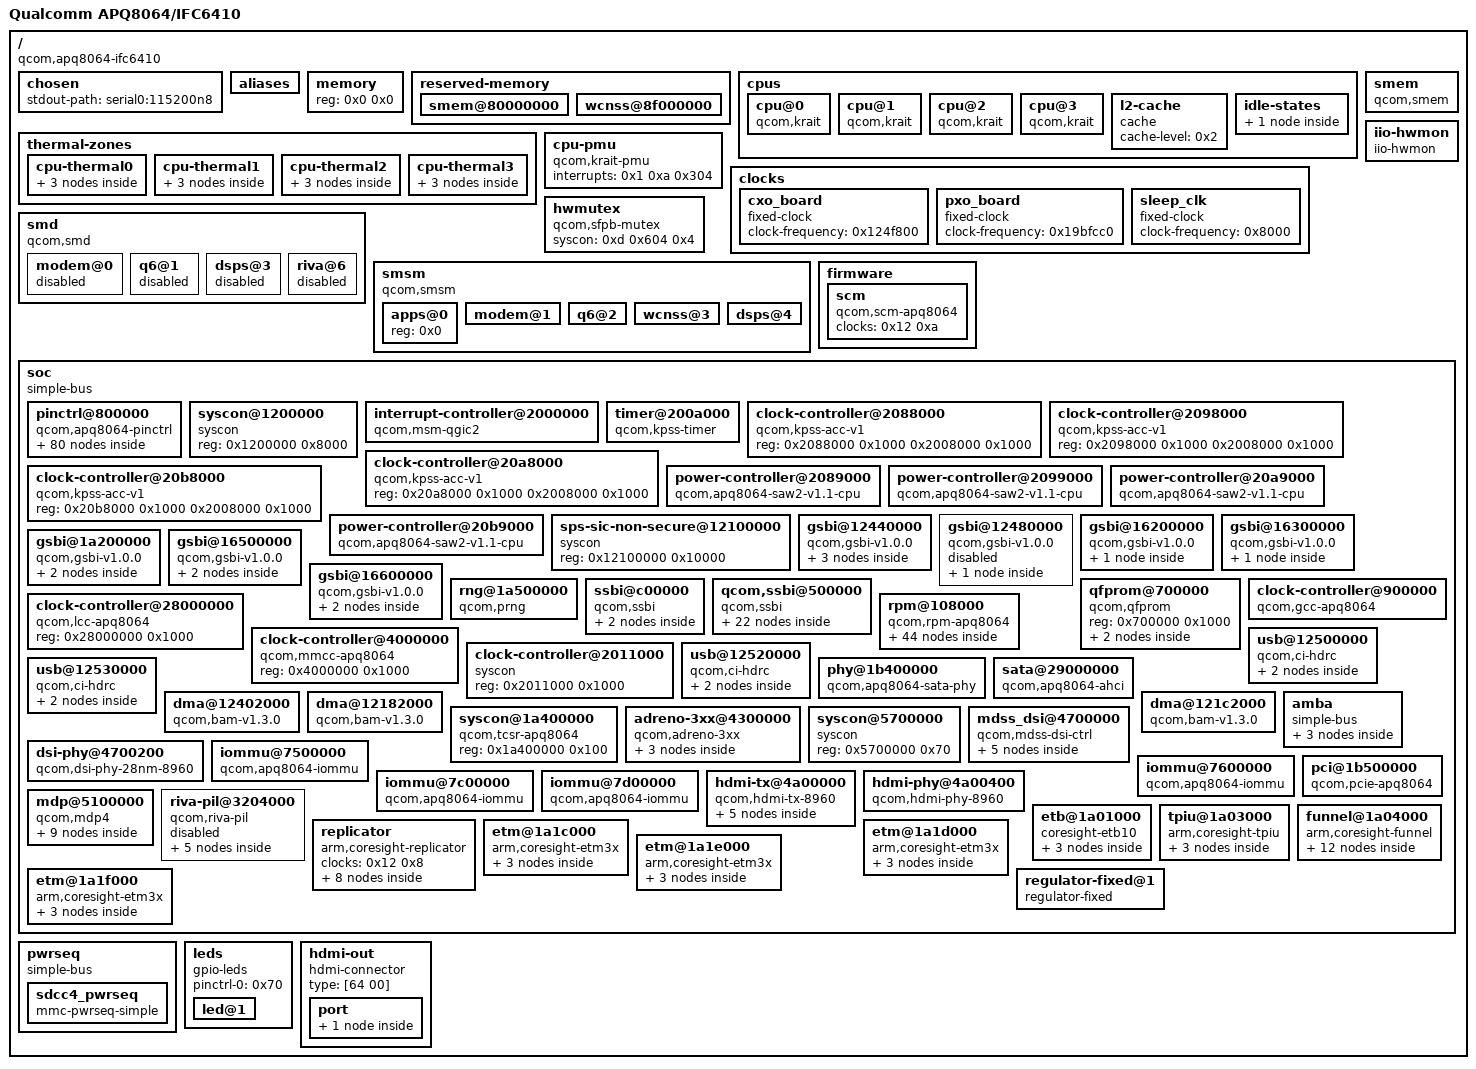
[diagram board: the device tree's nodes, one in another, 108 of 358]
/*
 * The code contained herein is licensed under the GNU General Public
 * License. You may obtain a copy of the GNU General Public License
 * Version 2 or later at the following locations:
 *
 * http://www.opensource.org/licenses/gpl-license.html
 * http://www.gnu.org/copyleft/gpl.html
 *
 * @TAG(OTHER_GPL)
 */

/dts-v1/;

/ {
	#address-cells = <0x1>;
	#size-cells = <0x1>;
	model = "Qualcomm APQ8064/IFC6410";
	compatible = "qcom,apq8064-ifc6410", "qcom,apq8064";
	interrupt-parent = <0x1>;

	chosen {
		stdout-path = "serial0:115200n8";
	};

	aliases {
		serial0 = "/soc/gsbi@16600000/serial@16640000";
		serial1 = "/soc/gsbi@16500000/serial@16540000";
		i2c0 = "/soc/gsbi@12440000/i2c@12460000";
		i2c1 = "/soc/gsbi@12480000/i2c@124a0000";
		i2c2 = "/soc/gsbi@16200000/i2c@16280000";
		i2c3 = "/soc/gsbi@16300000/i2c@16380000";
		spi0 = "/soc/gsbi@1a200000/spi@1a280000";
	};

	memory {
		device_type = "memory";
		reg = <0x0 0x0>;
	};

	reserved-memory {
		#address-cells = <0x1>;
		#size-cells = <0x1>;
		ranges;

		smem@80000000 {
			reg = <0x80000000 0x200000>;
			no-map;
			phandle = <0xe>;
		};

		wcnss@8f000000 {
			reg = <0x8f000000 0x700000>;
			no-map;
			phandle = <0x55>;
		};
	};

	cpus {
		#address-cells = <0x1>;
		#size-cells = <0x0>;

		cpu@0 {
			compatible = "qcom,krait";
			enable-method = "qcom,kpss-acc-v1";
			device_type = "cpu";
			reg = <0x0>;
			next-level-cache = <0x2>;
			qcom,acc = <0x3>;
			qcom,saw = <0x4>;
			cpu-idle-states = <0x5>;
			phandle = <0x66>;
		};

		cpu@1 {
			compatible = "qcom,krait";
			enable-method = "qcom,kpss-acc-v1";
			device_type = "cpu";
			reg = <0x1>;
			next-level-cache = <0x2>;
			qcom,acc = <0x6>;
			qcom,saw = <0x7>;
			cpu-idle-states = <0x5>;
			phandle = <0x68>;
		};

		cpu@2 {
			compatible = "qcom,krait";
			enable-method = "qcom,kpss-acc-v1";
			device_type = "cpu";
			reg = <0x2>;
			next-level-cache = <0x2>;
			qcom,acc = <0x8>;
			qcom,saw = <0x9>;
			cpu-idle-states = <0x5>;
			phandle = <0x6a>;
		};

		cpu@3 {
			compatible = "qcom,krait";
			enable-method = "qcom,kpss-acc-v1";
			device_type = "cpu";
			reg = <0x3>;
			next-level-cache = <0x2>;
			qcom,acc = <0xa>;
			qcom,saw = <0xb>;
			cpu-idle-states = <0x5>;
			phandle = <0x6c>;
		};

		l2-cache {
			compatible = "cache";
			cache-level = <0x2>;
			phandle = <0x2>;
		};

		idle-states {

			spc {
				compatible = "qcom,idle-state-spc", "arm,idle-state";
				entry-latency-us = <0x190>;
				exit-latency-us = <0x384>;
				min-residency-us = <0xbb8>;
				phandle = <0x5>;
			};
		};
	};

	thermal-zones {

		cpu-thermal0 {
			polling-delay-passive = <0xfa>;
			polling-delay = <0x3e8>;
			thermal-sensors = <0xc 0x7>;
			coefficients = <0x4af 0x0>;

			trips {

				trip0 {
					temperature = <0x124f8>;
					hysteresis = <0x7d0>;
					type = "passive";
				};

				trip1 {
					temperature = <0x1adb0>;
					hysteresis = <0x7d0>;
					type = "critical";
				};
			};
		};

		cpu-thermal1 {
			polling-delay-passive = <0xfa>;
			polling-delay = <0x3e8>;
			thermal-sensors = <0xc 0x8>;
			coefficients = <0x46c 0x0>;

			trips {

				trip0 {
					temperature = <0x124f8>;
					hysteresis = <0x7d0>;
					type = "passive";
				};

				trip1 {
					temperature = <0x1adb0>;
					hysteresis = <0x7d0>;
					type = "critical";
				};
			};
		};

		cpu-thermal2 {
			polling-delay-passive = <0xfa>;
			polling-delay = <0x3e8>;
			thermal-sensors = <0xc 0x9>;
			coefficients = <0x4af 0x0>;

			trips {

				trip0 {
					temperature = <0x124f8>;
					hysteresis = <0x7d0>;
					type = "passive";
				};

				trip1 {
					temperature = <0x1adb0>;
					hysteresis = <0x7d0>;
					type = "critical";
				};
			};
		};

		cpu-thermal3 {
			polling-delay-passive = <0xfa>;
			polling-delay = <0x3e8>;
			thermal-sensors = <0xc 0xa>;
			coefficients = <0x46c 0x0>;

			trips {

				trip0 {
					temperature = <0x124f8>;
					hysteresis = <0x7d0>;
					type = "passive";
				};

				trip1 {
					temperature = <0x1adb0>;
					hysteresis = <0x7d0>;
					type = "critical";
				};
			};
		};
	};

	cpu-pmu {
		compatible = "qcom,krait-pmu";
		interrupts = <0x1 0xa 0x304>;
	};

	clocks {

		cxo_board {
			compatible = "fixed-clock";
			#clock-cells = <0x0>;
			clock-frequency = <0x124f800>;
			phandle = <0x2f>;
		};

		pxo_board {
			compatible = "fixed-clock";
			#clock-cells = <0x0>;
			clock-frequency = <0x19bfcc0>;
		};

		sleep_clk {
			compatible = "fixed-clock";
			#clock-cells = <0x0>;
			clock-frequency = <0x8000>;
			phandle = <0x2e>;
		};
	};

	hwmutex {
		compatible = "qcom,sfpb-mutex";
		syscon = <0xd 0x604 0x4>;
		#hwlock-cells = <0x1>;
		phandle = <0xf>;
	};

	smem {
		compatible = "qcom,smem";
		memory-region = <0xe>;
		hwlocks = <0xf 0x3>;
	};

	smd {
		compatible = "qcom,smd";

		modem@0 {
			interrupts = <0x0 0x25 0x1>;
			qcom,ipc = <0x10 0x8 0x3>;
			qcom,smd-edge = <0x0>;
			status = "disabled";
		};

		q6@1 {
			interrupts = <0x0 0x5a 0x1>;
			qcom,ipc = <0x10 0x8 0xf>;
			qcom,smd-edge = <0x1>;
			status = "disabled";
		};

		dsps@3 {
			interrupts = <0x0 0x8a 0x1>;
			qcom,ipc = <0x11 0x4080 0x0>;
			qcom,smd-edge = <0x3>;
			status = "disabled";
		};

		riva@6 {
			interrupts = <0x0 0xc6 0x1>;
			qcom,ipc = <0x10 0x8 0x19>;
			qcom,smd-edge = <0x6>;
			status = "disabled";
		};
	};

	smsm {
		compatible = "qcom,smsm";
		#address-cells = <0x1>;
		#size-cells = <0x0>;
		qcom,ipc-1 = <0x10 0x8 0x4>;
		qcom,ipc-2 = <0x10 0x8 0xe>;
		qcom,ipc-3 = <0x10 0x8 0x17>;
		qcom,ipc-4 = <0x11 0x4094 0x0>;

		apps@0 {
			reg = <0x0>;
			#qcom,smem-state-cells = <0x1>;
			phandle = <0x5b>;
		};

		modem@1 {
			reg = <0x1>;
			interrupts = <0x0 0x26 0x1>;
			interrupt-controller;
			#interrupt-cells = <0x2>;
		};

		q6@2 {
			reg = <0x2>;
			interrupts = <0x0 0x59 0x1>;
			interrupt-controller;
			#interrupt-cells = <0x2>;
		};

		wcnss@3 {
			reg = <0x3>;
			interrupts = <0x0 0xcc 0x1>;
			interrupt-controller;
			#interrupt-cells = <0x2>;
			phandle = <0x54>;
		};

		dsps@4 {
			reg = <0x4>;
			interrupts = <0x0 0x89 0x1>;
			interrupt-controller;
			#interrupt-cells = <0x2>;
		};
	};

	firmware {

		scm {
			compatible = "qcom,scm-apq8064";
			clocks = <0x12 0xa>;
			clock-names = "core";
		};
	};

	iio-hwmon {
		compatible = "iio-hwmon";
		io-channels = <0x13 0x0 0x1 0x13 0x0 0x2 0x13 0x0 0x4 0x13 0x0 0xb 0x13 0x0 0xc 0x13 0x0 0xd 0x13 0x0 0xe>;
	};

	soc {
		#address-cells = <0x1>;
		#size-cells = <0x1>;
		ranges;
		compatible = "simple-bus";

		pinctrl@800000 {
			compatible = "qcom,apq8064-pinctrl";
			reg = <0x800000 0x4000>;
			gpio-controller;
			#gpio-cells = <0x2>;
			interrupt-controller;
			#interrupt-cells = <0x2>;
			interrupts = <0x0 0x10 0x4>;
			pinctrl-names = "default";
			pinctrl-0 = <0x14>;
			phandle = <0x20>;

			sdc4-gpios {
				phandle = <0x40>;

				pios {
					pins = "gpio63", "gpio64", "gpio65", "gpio66", "gpio67", "gpio68";
					function = "sdc4";
				};
			};

			sdcc1-pin-active {
				phandle = <0x39>;

				clk {
					pins = "sdc1_clk";
					drive-strengh = <0x10>;
					bias-disable;
				};

				cmd {
					pins = "sdc1_cmd";
					drive-strengh = <0xa>;
					bias-pull-up;
				};

				data {
					pins = "sdc1_data";
					drive-strengh = <0xa>;
					bias-pull-up;
				};
			};

			sdcc3-pin-active {

				clk {
					pins = "sdc3_clk";
					drive-strengh = <0x8>;
					bias-disable;
				};

				cmd {
					pins = "sdc3_cmd";
					drive-strengh = <0x8>;
					bias-pull-up;
				};

				data {
					pins = "sdc3_data";
					drive-strengh = <0x8>;
					bias-pull-up;
				};
			};

			ps_hold {
				phandle = <0x14>;

				mux {
					pins = "gpio78";
					function = "ps_hold";
				};
			};

			i2c1 {
				phandle = <0x16>;

				mux {
					pins = "gpio20", "gpio21";
					function = "gsbi1";
				};

				pinconf {
					pins = "gpio20", "gpio21";
					drive-strength = <0x10>;
					bias-disable;
				};
			};

			i2c1_pins_sleep {
				phandle = <0x17>;

				mux {
					pins = "gpio20", "gpio21";
					function = "gpio";
				};

				pinconf {
					pins = "gpio20", "gpio21";
					drive-strength = <0x2>;
					bias-disable = <0x0>;
				};
			};

			gsbi1_uart_2pins {

				mux {
					pins = "gpio18", "gpio19";
					function = "gsbi1";
				};
			};

			gsbi1_uart_4pins {

				mux {
					pins = "gpio18", "gpio19", "gpio20", "gpio21";
					function = "gsbi1";
				};
			};

			i2c2 {
				phandle = <0x18>;

				mux {
					pins = "gpio24", "gpio25";
					function = "gsbi2";
				};

				pinconf {
					pins = "gpio24", "gpio25";
					drive-strength = <0x10>;
					bias-disable;
				};
			};

			i2c2_pins_sleep {
				phandle = <0x19>;

				mux {
					pins = "gpio24", "gpio25";
					function = "gpio";
				};

				pinconf {
					pins = "gpio24", "gpio25";
					drive-strength = <0x2>;
					bias-disable = <0x0>;
				};
			};

			i2c3 {
				phandle = <0x1a>;

				mux {
					pins = "gpio8", "gpio9";
					function = "gsbi3";
				};

				pinconf {
					pins = "gpio8", "gpio9";
					drive-strength = <0x10>;
					bias-disable;
				};
			};

			i2c3_pins_sleep {
				phandle = <0x1b>;

				mux {
					pins = "gpio8", "gpio9";
					function = "gpio";
				};

				pinconf {
					pins = "gpio8", "gpio9";
					drive-strength = <0x2>;
					bias-disable = <0x0>;
				};
			};

			i2c4 {
				phandle = <0x1c>;

				mux {
					pins = "gpio12", "gpio13";
					function = "gsbi4";
				};

				pinconf {
					pins = "gpio12", "gpio13";
					drive-strength = <0x10>;
					bias-disable;
				};
			};

			i2c4_pins_sleep {
				phandle = <0x1d>;

				mux {
					pins = "gpio12", "gpio13";
					function = "gpio";
				};

				pinconf {
					pins = "gpio12", "gpio13";
					drive-strength = <0x2>;
					bias-disable = <0x0>;
				};
			};

			spi5_default {
				phandle = <0x1e>;

				pinmux {
					pins = "gpio51", "gpio52", "gpio54";
					function = "gsbi5";
				};

				pinmux_cs {
					function = "gpio";
					pins = "gpio53";
				};

				pinconf {
					pins = "gpio51", "gpio52", "gpio54";
					drive-strength = <0x10>;
					bias-disable;
				};

				pinconf_cs {
					pins = "gpio53";
					drive-strength = <0x10>;
					bias-disable;
					output-high;
				};
			};

			spi5_sleep {
				phandle = <0x1f>;

				pinmux {
					function = "gpio";
					pins = "gpio51", "gpio52", "gpio53", "gpio54";
				};

				pinconf {
					pins = "gpio51", "gpio52", "gpio53", "gpio54";
					drive-strength = <0x2>;
					bias-pull-down;
				};
			};

			i2c6 {
				phandle = <0x22>;

				mux {
					pins = "gpio16", "gpio17";
					function = "gsbi6";
				};

				pinconf {
					pins = "gpio16", "gpio17";
					drive-strength = <0x10>;
					bias-disable;
				};
			};

			i2c6_pins_sleep {
				phandle = <0x23>;

				mux {
					pins = "gpio16", "gpio17";
					function = "gpio";
				};

				pinconf {
					pins = "gpio16", "gpio17";
					drive-strength = <0x2>;
					bias-disable = <0x0>;
				};
			};

			gsbi6_uart_2pins {

				mux {
					pins = "gpio14", "gpio15";
					function = "gsbi6";
				};
			};

			gsbi6_uart_4pins {
				phandle = <0x21>;

				mux {
					pins = "gpio14", "gpio15", "gpio16", "gpio17";
					function = "gsbi6";
				};
			};

			gsbi7_uart_2pins {
				phandle = <0x24>;

				mux {
					pins = "gpio82", "gpio83";
					function = "gsbi7";
				};
			};

			gsbi7_uart_4pins {

				mux {
					pins = "gpio82", "gpio83", "gpio84", "gpio85";
					function = "gsbi7";
				};
			};

			i2c7 {
				phandle = <0x25>;

				mux {
					pins = "gpio84", "gpio85";
					function = "gsbi7";
				};

				pinconf {
					pins = "gpio84", "gpio85";
					drive-strength = <0x10>;
					bias-disable;
				};
			};

			i2c7_pins_sleep {
				phandle = <0x26>;

				mux {
					pins = "gpio84", "gpio85";
					function = "gpio";
				};

				pinconf {
					pins = "gpio84", "gpio85";
					drive-strength = <0x2>;
					bias-disable = <0x0>;
				};
			};

			riva-fm-active {
				pins = "gpio14", "gpio15";
				function = "riva_fm";
			};

			riva-bt-active {
				pins = "gpio16", "gpio17";
				function = "riva_bt";
			};

			riva-wlan-active {
				pins = "gpio64", "gpio65", "gpio66", "gpio67", "gpio68";
				function = "riva_wlan";
				drive-strength = <0x6>;
				bias-pull-down;
			};

			hdmi-pinctrl {
				phandle = <0x4c>;

				mux {
					pins = "gpio70", "gpio71", "gpio72";
					function = "hdmi";
				};

				pinconf_ddc {
					pins = "gpio70", "gpio71";
					bias-pull-up;
					drive-strength = <0x2>;
				};

				pinconf_hpd {
					pins = "gpio72";
					bias-pull-down;
					drive-strength = <0x10>;
				};
			};

			card_detect {
				phandle = <0x3e>;

				mux {
					pins = "gpio26";
					function = "gpio";
					bias-disable;
				};
			};

			pcie_pinmux {
				phandle = <0x4b>;

				mux {
					pins = "gpio27";
					function = "gpio";
				};

				conf {
					pins = "gpio27";
					drive-strength = <0xc>;
					bias-disable;
				};
			};
		};

		syscon@1200000 {
			compatible = "syscon";
			reg = <0x1200000 0x8000>;
			phandle = <0xd>;
		};

		interrupt-controller@2000000 {
			compatible = "qcom,msm-qgic2";
			interrupt-controller;
			#interrupt-cells = <0x3>;
			reg = <0x2000000 0x1000 0x2002000 0x1000>;
			phandle = <0x1>;
		};

		timer@200a000 {
			compatible = "qcom,kpss-timer", "qcom,kpss-wdt-apq8064", "qcom,msm-timer";
			interrupts = <0x1 0x1 0x301 0x1 0x2 0x301 0x1 0x3 0x301>;
			reg = <0x200a000 0x100>;
			clock-frequency = <0x19bfcc0 0x8000>;
			cpu-offset = <0x80000>;
		};

		clock-controller@2088000 {
			compatible = "qcom,kpss-acc-v1";
			reg = <0x2088000 0x1000 0x2008000 0x1000>;
			phandle = <0x3>;
		};

		clock-controller@2098000 {
			compatible = "qcom,kpss-acc-v1";
			reg = <0x2098000 0x1000 0x2008000 0x1000>;
			phandle = <0x6>;
		};

		clock-controller@20a8000 {
			compatible = "qcom,kpss-acc-v1";
			reg = <0x20a8000 0x1000 0x2008000 0x1000>;
			phandle = <0x8>;
		};

		clock-controller@20b8000 {
			compatible = "qcom,kpss-acc-v1";
			reg = <0x20b8000 0x1000 0x2008000 0x1000>;
			phandle = <0xa>;
		};

		power-controller@2089000 {
			compatible = "qcom,apq8064-saw2-v1.1-cpu", "qcom,saw2";
			reg = <0x2089000 0x1000 0x2009000 0x1000>;
			regulator;
			phandle = <0x4>;
		};

		power-controller@2099000 {
			compatible = "qcom,apq8064-saw2-v1.1-cpu", "qcom,saw2";
			reg = <0x2099000 0x1000 0x2009000 0x1000>;
			regulator;
			phandle = <0x7>;
		};

		power-controller@20a9000 {
			compatible = "qcom,apq8064-saw2-v1.1-cpu", "qcom,saw2";
			reg = <0x20a9000 0x1000 0x2009000 0x1000>;
			regulator;
			phandle = <0x9>;
		};

		power-controller@20b9000 {
			compatible = "qcom,apq8064-saw2-v1.1-cpu", "qcom,saw2";
			reg = <0x20b9000 0x1000 0x2009000 0x1000>;
			regulator;
			phandle = <0xb>;
		};

		sps-sic-non-secure@12100000 {
			compatible = "syscon";
			reg = <0x12100000 0x10000>;
			phandle = <0x11>;
		};

		gsbi@12440000 {
			status = "okay";
			compatible = "qcom,gsbi-v1.0.0";
			cell-index = <0x1>;
			reg = <0x12440000 0x100>;
			clocks = <0xc 0x93>;
			clock-names = "iface";
			#address-cells = <0x1>;
			#size-cells = <0x1>;
			ranges;
			syscon-tcsr = <0x15>;
			qcom,mode = <0x2>;

			serial@12450000 {
				compatible = "qcom,msm-uartdm-v1.3", "qcom,msm-uartdm";
				reg = <0x12450000 0x100 0x12400000 0x3>;
				interrupts = <0x0 0xc1 0x4>;
				clocks = <0xc 0xa0 0xc 0x93>;
				clock-names = "core", "iface";
				status = "disabled";
			};

			i2c@12460000 {
				compatible = "qcom,i2c-qup-v1.1.1";
				pinctrl-0 = <0x16>;
				pinctrl-1 = <0x17>;
				pinctrl-names = "default", "sleep";
				reg = <0x12460000 0x1000>;
				interrupts = <0x0 0xc2 0x4>;
				clocks = <0xc 0xb8 0xc 0x93>;
				clock-names = "core", "iface";
				#address-cells = <0x1>;
				#size-cells = <0x0>;
				status = "okay";
				clock-frequency = <0x30d40>;

				eeprom@52 {
					compatible = "atmel,24c128";
					reg = <0x52>;
					pagesize = <0x20>;
				};
			};
		};

		gsbi@12480000 {
			status = "disabled";
			compatible = "qcom,gsbi-v1.0.0";
			cell-index = <0x2>;
			reg = <0x12480000 0x100>;
			clocks = <0xc 0x94>;
			clock-names = "iface";
			#address-cells = <0x1>;
			#size-cells = <0x1>;
			ranges;
			syscon-tcsr = <0x15>;

			i2c@124a0000 {
				compatible = "qcom,i2c-qup-v1.1.1";
				reg = <0x124a0000 0x1000>;
				pinctrl-0 = <0x18>;
				pinctrl-1 = <0x19>;
				pinctrl-names = "default", "sleep";
				interrupts = <0x0 0xc4 0x4>;
				clocks = <0xc 0xba 0xc 0x94>;
				clock-names = "core", "iface";
				#address-cells = <0x1>;
				#size-cells = <0x0>;
				status = "disabled";
			};
		};

		gsbi@16200000 {
			status = "okay";
			compatible = "qcom,gsbi-v1.0.0";
			cell-index = <0x3>;
			reg = <0x16200000 0x100>;
			clocks = <0xc 0x95>;
			clock-names = "iface";
			#address-cells = <0x1>;
			#size-cells = <0x1>;
			ranges;
			qcom,mode = <0x2>;

			i2c@16280000 {
				compatible = "qcom,i2c-qup-v1.1.1";
				pinctrl-0 = <0x1a>;
				pinctrl-1 = <0x1b>;
				pinctrl-names = "default", "sleep";
				reg = <0x16280000 0x1000>;
				interrupts = <0x0 0x97 0x4>;
				clocks = <0xc 0xbc 0xc 0x95>;
				clock-names = "core", "iface";
				#address-cells = <0x1>;
				#size-cells = <0x0>;
				status = "okay";
			};
		};

		gsbi@16300000 {
			status = "okay";
			compatible = "qcom,gsbi-v1.0.0";
			cell-index = <0x4>;
			reg = <0x16300000 0x3>;
			clocks = <0xc 0x96>;
			clock-names = "iface";
			#address-cells = <0x1>;
			#size-cells = <0x1>;
			ranges;
			qcom,mode = <0x2>;

			i2c@16380000 {
				compatible = "qcom,i2c-qup-v1.1.1";
				pinctrl-0 = <0x1c>;
				pinctrl-1 = <0x1d>;
				pinctrl-names = "default", "sleep";
				reg = <0x16380000 0x1000>;
				interrupts = <0x0 0x99 0x4>;
				clocks = <0xc 0xbe 0xc 0x96>;
				clock-names = "core", "iface";
				status = "okay";
			};
		};

		gsbi@1a200000 {
			status = "okay";
			compatible = "qcom,gsbi-v1.0.0";
			cell-index = <0x5>;
			reg = <0x1a200000 0x3>;
			clocks = <0xc 0x97>;
			clock-names = "iface";
			#address-cells = <0x1>;
			#size-cells = <0x1>;
			ranges;
			qcom,mode = <0x3>;

			serial@1a240000 {
				compatible = "qcom,msm-uartdm-v1.3", "qcom,msm-uartdm";
				reg = <0x1a240000 0x100 0x1a200000 0x3>;
				interrupts = <0x0 0x9a 0x4>;
				clocks = <0xc 0xa8 0xc 0x97>;
				clock-names = "core", "iface";
				status = "disabled";
			};

			spi@1a280000 {
				compatible = "qcom,spi-qup-v1.1.1";
				reg = <0x1a280000 0x1000>;
				interrupts = <0x0 0x9b 0x4>;
				pinctrl-0 = <0x1e>;
				pinctrl-1 = <0x1f>;
				pinctrl-names = "default", "sleep";
				clocks = <0xc 0xc0 0xc 0x97>;
				clock-names = "core", "iface";
				status = "okay";
				#address-cells = <0x1>;
				#size-cells = <0x0>;
				num-cs = <0x1>;
				cs-gpios = <0x20 0x35 0x0>;
			};
		};

		gsbi@16500000 {
			status = "ok";
			compatible = "qcom,gsbi-v1.0.0";
			cell-index = <0x6>;
			reg = <0x16500000 0x3>;
			clocks = <0xc 0x98>;
			clock-names = "iface";
			#address-cells = <0x1>;
			#size-cells = <0x1>;
			ranges;
			qcom,mode = <0x4>;

			serial@16540000 {
				compatible = "qcom,msm-uartdm-v1.3", "qcom,msm-uartdm";
				reg = <0x16540000 0x100 0x16500000 0x3>;
				interrupts = <0x0 0x9c 0x4>;
				clocks = <0xc 0xaa 0xc 0x98>;
				clock-names = "core", "iface";
				status = "ok";
				pinctrl-names = "default";
				pinctrl-0 = <0x21>;
			};

			i2c@16580000 {
				compatible = "qcom,i2c-qup-v1.1.1";
				pinctrl-0 = <0x22>;
				pinctrl-1 = <0x23>;
				pinctrl-names = "default", "sleep";
				reg = <0x16580000 0x1000>;
				interrupts = <0x0 0x9d 0x4>;
				clocks = <0xc 0xc2 0xc 0x98>;
				clock-names = "core", "iface";
				status = "disabled";
			};
		};

		gsbi@16600000 {
			status = "ok";
			compatible = "qcom,gsbi-v1.0.0";
			cell-index = <0x7>;
			reg = <0x16600000 0x100>;
			clocks = <0xc 0x99>;
			clock-names = "iface";
			#address-cells = <0x1>;
			#size-cells = <0x1>;
			ranges;
			syscon-tcsr = <0x15>;
			qcom,mode = <0x6>;

			serial@16640000 {
				compatible = "qcom,msm-uartdm-v1.3", "qcom,msm-uartdm";
				reg = <0x16640000 0x1000 0x16600000 0x1000>;
				interrupts = <0x0 0x9e 0x4>;
				clocks = <0xc 0xac 0xc 0x99>;
				clock-names = "core", "iface";
				status = "ok";
				pinctrl-names = "default";
				pinctrl-0 = <0x24>;
			};

			i2c@16680000 {
				compatible = "qcom,i2c-qup-v1.1.1";
				pinctrl-0 = <0x25>;
				pinctrl-1 = <0x26>;
				pinctrl-names = "default", "sleep";
				reg = <0x16680000 0x1000>;
				interrupts = <0x0 0x9f 0x4>;
				clocks = <0xc 0xc4 0xc 0x99>;
				clock-names = "core", "iface";
				status = "disabled";
			};
		};

		rng@1a500000 {
			compatible = "qcom,prng";
			reg = <0x1a500000 0x200>;
			clocks = <0xc 0x108>;
			clock-names = "core";
		};

		ssbi@c00000 {
			compatible = "qcom,ssbi";
			reg = <0xc00000 0x1000>;
			qcom,controller-type = "pmic-arbiter";

			pmic@1 {
				compatible = "qcom,pm8821";
				interrupt-parent = <0x20>;
				interrupts = <0x4c 0x8>;
				#interrupt-cells = <0x2>;
				interrupt-controller;
				#address-cells = <0x1>;
				#size-cells = <0x0>;

				mpps@50 {
					compatible = "qcom,pm8821-mpp", "qcom,ssbi-mpp";
					reg = <0x50>;
					interrupts = <0x18 0x0 0x19 0x0 0x1a 0x0 0x1b 0x0>;
					gpio-controller;
					#gpio-cells = <0x2>;
				};
			};
		};

		qcom,ssbi@500000 {
			compatible = "qcom,ssbi";
			reg = <0x500000 0x1000>;
			qcom,controller-type = "pmic-arbiter";

			pmic@0 {
				compatible = "qcom,pm8921";
				interrupt-parent = <0x20>;
				interrupts = <0x4a 0x8>;
				#interrupt-cells = <0x2>;
				interrupt-controller;
				#address-cells = <0x1>;
				#size-cells = <0x0>;
				phandle = <0x27>;

				gpio@150 {
					compatible = "qcom,pm8921-gpio", "qcom,ssbi-gpio";
					reg = <0x150>;
					interrupts = <0xc0 0x0 0xc1 0x0 0xc2 0x0 0xc3 0x0 0xc4 0x0 0xc5 0x0 0xc6 0x0 0xc7 0x0 0xc8 0x0 0xc9 0x0 0xca 0x0 0xcb 0x0 0xcc 0x0 0xcd 0x0 0xce 0x0 0xcf 0x0 0xd0 0x0 0xd1 0x0 0xd2 0x0 0xd3 0x0 0xd4 0x0 0xd5 0x0 0xd6 0x0 0xd7 0x0 0xd8 0x0 0xd9 0x0 0xda 0x0 0xdb 0x0 0xdc 0x0 0xdd 0x0 0xde 0x0 0xdf 0x0 0xe0 0x0 0xe1 0x0 0xe2 0x0 0xe3 0x0 0xe4 0x0 0xe5 0x0 0xe6 0x0 0xe7 0x0 0xe8 0x0 0xe9 0x0 0xea 0x0 0xeb 0x0>;
					gpio-controller;
					#gpio-cells = <0x2>;
					phandle = <0x6f>;

					wlan-gpios {
						phandle = <0x6e>;

						pios {
							pins = "gpio43";
							function = "normal";
							bias-disable;
							power-source = <0x2>;
						};
					};

					nled {
						phandle = <0x70>;

						pios {
							pins = "gpio18";
							function = "normal";
							bias-disable;
							power-source = <0x2>;
						};
					};
				};

				mpps@50 {
					compatible = "qcom,pm8921-mpp", "qcom,ssbi-mpp";
					reg = <0x50>;
					gpio-controller;
					#gpio-cells = <0x2>;
					interrupts = <0x80 0x0 0x81 0x0 0x82 0x0 0x83 0x0 0x84 0x0 0x85 0x0 0x86 0x0 0x87 0x0 0x88 0x0 0x89 0x0 0x8a 0x0 0x8b 0x0>;
				};

				rtc@11d {
					compatible = "qcom,pm8921-rtc";
					interrupt-parent = <0x27>;
					interrupts = <0x27 0x1>;
					reg = <0x11d>;
					allow-set-time;
				};

				pwrkey@1c {
					compatible = "qcom,pm8921-pwrkey";
					reg = <0x1c>;
					interrupt-parent = <0x27>;
					interrupts = <0x32 0x1 0x33 0x1>;
					debounce = <0x3d09>;
					pull-up;
				};

				xoadc@197 {
					compatible = "qcom,pm8921-adc";
					reg = <0xc5>;
					interrupts-extended = <0x27 0x4e 0x1>;
					#address-cells = <0x2>;
					#size-cells = <0x0>;
					#io-channel-cells = <0x2>;
					phandle = <0x13>;

					adc-channel@00 {
						reg = <0x0 0x0>;
					};

					adc-channel@01 {
						reg = <0x0 0x1>;
					};

					adc-channel@02 {
						reg = <0x0 0x2>;
					};

					adc-channel@04 {
						reg = <0x0 0x4>;
					};

					adc-channel@08 {
						reg = <0x0 0x8>;
					};

					adc-channel@09 {
						reg = <0x0 0x9>;
					};

					adc-channel@0a {
						reg = <0x0 0xa>;
					};

					adc-channel@0b {
						reg = <0x0 0xb>;
					};

					adc-channel@0c {
						reg = <0x0 0xc>;
					};

					adc-channel@0d {
						reg = <0x0 0xd>;
					};

					adc-channel@0e {
						reg = <0x0 0xe>;
					};

					adc-channel@0f {
						reg = <0x0 0xf>;
					};
				};
			};
		};

		qfprom@700000 {
			compatible = "qcom,qfprom";
			reg = <0x700000 0x1000>;
			#address-cells = <0x1>;
			#size-cells = <0x1>;
			ranges;

			calib {
				reg = <0x404 0x10>;
				phandle = <0x28>;
			};

			backup_calib {
				reg = <0x414 0x10>;
				phandle = <0x29>;
			};
		};

		clock-controller@900000 {
			compatible = "qcom,gcc-apq8064";
			reg = <0x900000 0x4000>;
			nvmem-cells = <0x28 0x29>;
			nvmem-cell-names = "calib", "calib_backup";
			#clock-cells = <0x1>;
			#reset-cells = <0x1>;
			#thermal-sensor-cells = <0x1>;
			phandle = <0xc>;
		};

		clock-controller@28000000 {
			compatible = "qcom,lcc-apq8064";
			reg = <0x28000000 0x1000>;
			#clock-cells = <0x1>;
			#reset-cells = <0x1>;
		};

		clock-controller@4000000 {
			compatible = "qcom,mmcc-apq8064";
			reg = <0x4000000 0x1000>;
			#clock-cells = <0x1>;
			#reset-cells = <0x1>;
			phandle = <0x44>;
		};

		clock-controller@2011000 {
			compatible = "syscon";
			reg = <0x2011000 0x1000>;
			phandle = <0x10>;
		};

		rpm@108000 {
			compatible = "qcom,rpm-apq8064";
			reg = <0x108000 0x1000>;
			qcom,ipc = <0x10 0x8 0x2>;
			interrupts = <0x0 0x13 0x1 0x0 0x15 0x1 0x0 0x16 0x1>;
			interrupt-names = "ack", "err", "wakeup";

			clock-controller {
				compatible = "qcom,rpmcc-apq8064", "qcom,rpmcc";
				#clock-cells = <0x1>;
				phandle = <0x12>;
			};

			regulators {
				compatible = "qcom,rpm-pm8921-regulators";
				vin_lvs1_3_6-supply = <0x2a>;
				vin_lvs2-supply = <0x2b>;
				vin_lvs4_5_7-supply = <0x2a>;
				vdd_l1_l2_l12_l18-supply = <0x2a>;
				vdd_l24-supply = <0x2b>;
				vdd_l25-supply = <0x2b>;
				vdd_l26-supply = <0x2c>;
				vdd_l27-supply = <0x2c>;
				vdd_l28-supply = <0x2c>;

				s1 {
					regulator-always-on;
					regulator-min-microvolt = <0x12b128>;
					regulator-max-microvolt = <0x12b128>;
					qcom,switch-mode-frequency = <0x30d400>;
					bias-pull-down;
					phandle = <0x2b>;
				};

				s2 {
					phandle = <0x57>;
				};

				s3 {
					regulator-min-microvolt = <0xf4240>;
					regulator-max-microvolt = <0x155cc0>;
					qcom,switch-mode-frequency = <0x493e00>;
					phandle = <0x49>;
				};

				s4 {
					regulator-min-microvolt = <0x1b7740>;
					regulator-max-microvolt = <0x1b7740>;
					qcom,switch-mode-frequency = <0x30d400>;
					phandle = <0x2a>;
				};

				s7 {
					regulator-min-microvolt = <0x13d620>;
					regulator-max-microvolt = <0x13d620>;
					qcom,switch-mode-frequency = <0x30d400>;
					phandle = <0x2c>;
				};

				s8 {
				};

				l1 {
				};

				l2 {
				};

				l3 {
					regulator-min-microvolt = <0x2e8a10>;
					regulator-max-microvolt = <0x325aa0>;
					bias-pull-down;
					phandle = <0x31>;
				};

				l4 {
					regulator-min-microvolt = <0xf4240>;
					regulator-max-microvolt = <0x1b7740>;
					bias-pull-down;
					phandle = <0x32>;
				};

				l5 {
					regulator-min-microvolt = <0x29f630>;
					regulator-max-microvolt = <0x2dc6c0>;
					bias-pull-down;
					phandle = <0x3b>;
				};

				l6 {
					regulator-min-microvolt = <0x2d0370>;
					regulator-max-microvolt = <0x2d0370>;
					bias-pull-down;
					phandle = <0x3d>;
				};

				l7 {
				};

				l8 {
				};

				l9 {
				};

				l10 {
					phandle = <0x58>;
				};

				l11 {
				};

				l12 {
				};

				l14 {
				};

				l15 {
				};

				l16 {
				};

				l17 {
				};

				l18 {
				};

				l21 {
				};

				l22 {
				};

				l23 {
					regulator-min-microvolt = <0x19f0a0>;
					regulator-max-microvolt = <0x1cfde0>;
					bias-pull-down;
					phandle = <0x35>;
				};

				l24 {
					phandle = <0x56>;
				};

				l25 {
				};

				l26 {
				};

				l27 {
				};

				l28 {
				};

				l29 {
				};

				lvs1 {
					bias-pull-down;
					phandle = <0x42>;
				};

				lvs2 {
					phandle = <0x59>;
				};

				lvs3 {
				};

				lvs4 {
				};

				lvs5 {
				};

				lvs6 {
					bias-pull-down;
					phandle = <0x4a>;
				};

				lvs7 {
				};

				usb-switch {
				};

				hdmi-switch {
					bias-pull-down;
					phandle = <0x4e>;
				};

				ncp {
				};
			};
		};

		usb@12500000 {
			compatible = "qcom,ci-hdrc";
			reg = <0x12500000 0x200 0x12500200 0x200>;
			interrupts = <0x0 0x64 0x4>;
			clocks = <0xc 0x80 0xc 0x7e>;
			clock-names = "core", "iface";
			assigned-clocks = <0xc 0x80>;
			assigned-clock-rates = <0x3938700>;
			resets = <0xc 0x40>;
			reset-names = "core";
			phy_type = "ulpi";
			ahb-burst-config = <0x0>;
			phys = <0x2d>;
			phy-names = "usb-phy";
			status = "okay";
			#reset-cells = <0x1>;
			dr_mode = "otg";
			phandle = <0x30>;

			ulpi {

				phy {
					compatible = "qcom,usb-hs-phy-apq8064", "qcom,usb-hs-phy";
					clocks = <0x2e 0x2f>;
					clock-names = "sleep", "ref";
					resets = <0x30 0x0>;
					reset-names = "por";
					#phy-cells = <0x0>;
					v3p3-supply = <0x31>;
					v1p8-supply = <0x32>;
					phandle = <0x2d>;
				};
			};
		};

		usb@12520000 {
			compatible = "qcom,ci-hdrc";
			reg = <0x12520000 0x200 0x12520200 0x200>;
			interrupts = <0x0 0xbc 0x4>;
			clocks = <0xc 0x129 0xc 0x127>;
			clock-names = "core", "iface";
			assigned-clocks = <0xc 0x129>;
			assigned-clock-rates = <0x3938700>;
			resets = <0xc 0x64>;
			reset-names = "core";
			phy_type = "ulpi";
			ahb-burst-config = <0x0>;
			phys = <0x33>;
			phy-names = "usb-phy";
			status = "okay";
			#reset-cells = <0x1>;
			dr_mode = "host";
			phandle = <0x34>;

			ulpi {

				phy {
					compatible = "qcom,usb-hs-phy-apq8064", "qcom,usb-hs-phy";
					#phy-cells = <0x0>;
					clocks = <0x2e 0x2f>;
					clock-names = "sleep", "ref";
					resets = <0x34 0x0>;
					reset-names = "por";
					v3p3-supply = <0x31>;
					v1p8-supply = <0x35>;
					phandle = <0x33>;
				};
			};
		};

		usb@12530000 {
			compatible = "qcom,ci-hdrc";
			reg = <0x12530000 0x200 0x12530200 0x200>;
			interrupts = <0x0 0xd7 0x4>;
			clocks = <0xc 0x12c 0xc 0x12a>;
			clock-names = "core", "iface";
			assigned-clocks = <0xc 0x12c>;
			assigned-clock-rates = <0x3938700>;
			resets = <0xc 0x65>;
			reset-names = "core";
			phy_type = "ulpi";
			ahb-burst-config = <0x0>;
			phys = <0x36>;
			phy-names = "usb-phy";
			status = "okay";
			#reset-cells = <0x1>;
			dr_mode = "host";
			phandle = <0x37>;

			ulpi {

				phy {
					compatible = "qcom,usb-hs-phy-apq8064", "qcom,usb-hs-phy";
					#phy-cells = <0x0>;
					clocks = <0x2e 0x2f>;
					clock-names = "sleep", "ref";
					resets = <0x37 0x0>;
					reset-names = "por";
					v3p3-supply = <0x31>;
					v1p8-supply = <0x35>;
					phandle = <0x36>;
				};
			};
		};

		phy@1b400000 {
			compatible = "qcom,apq8064-sata-phy";
			status = "okay";
			reg = <0x1b400000 0x200>;
			reg-names = "phy_mem";
			clocks = <0xc 0x12d>;
			clock-names = "cfg";
			#phy-cells = <0x0>;
			phandle = <0x38>;
		};

		sata@29000000 {
			compatible = "qcom,apq8064-ahci", "generic-ahci";
			status = "okay";
			reg = <0x29000000 0x180>;
			interrupts = <0x0 0xd1 0x4>;
			clocks = <0xc 0x3b 0xc 0xed 0xc 0x12e 0xc 0xef 0xc 0xf0>;
			clock-names = "slave_iface", "iface", "bus", "rxoob", "core_pmalive";
			assigned-clocks = <0xc 0xef 0xc 0xf0>;
			assigned-clock-rates = <0x5f5e100 0x5f5e100>;
			phys = <0x38>;
			phy-names = "sata-phy";
			ports-implemented = <0x1>;
			target-supply = <0x2a>;
		};

		dma@12402000 {
			compatible = "qcom,bam-v1.3.0";
			reg = <0x12402000 0x8000>;
			interrupts = <0x0 0x62 0x4>;
			clocks = <0xc 0x6e>;
			clock-names = "bam_clk";
			#dma-cells = <0x1>;
			qcom,ee = <0x0>;
			phandle = <0x3a>;
		};

		dma@12182000 {
			compatible = "qcom,bam-v1.3.0";
			reg = <0x12182000 0x8000>;
			interrupts = <0x0 0x60 0x4>;
			clocks = <0xc 0x70>;
			clock-names = "bam_clk";
			#dma-cells = <0x1>;
			qcom,ee = <0x0>;
			phandle = <0x3c>;
		};

		dma@121c2000 {
			compatible = "qcom,bam-v1.3.0";
			reg = <0x121c2000 0x8000>;
			interrupts = <0x0 0x5f 0x4>;
			clocks = <0xc 0x71>;
			clock-names = "bam_clk";
			#dma-cells = <0x1>;
			qcom,ee = <0x0>;
			phandle = <0x3f>;
		};

		amba {
			compatible = "simple-bus";
			#address-cells = <0x1>;
			#size-cells = <0x1>;
			ranges;

			sdcc@12400000 {
				status = "okay";
				compatible = "arm,pl18x", "arm,primecell";
				pinctrl-names = "default";
				pinctrl-0 = <0x39>;
				arm,primecell-periphid = <0x51180>;
				reg = <0x12400000 0x2000>;
				interrupts = <0x0 0x68 0x4>;
				interrupt-names = "cmd_irq";
				clocks = <0xc 0x78 0xc 0x6e>;
				clock-names = "mclk", "apb_pclk";
				bus-width = <0x8>;
				max-frequency = <0x5b8d800>;
				non-removable;
				cap-sd-highspeed;
				cap-mmc-highspeed;
				dmas = <0x3a 0x2 0x3a 0x1>;
				dma-names = "tx", "rx";
				vmmc-supply = <0x3b>;
				vqmmc-supply = <0x2a>;
			};

			sdcc@12180000 {
				compatible = "arm,pl18x", "arm,primecell";
				arm,primecell-periphid = <0x51180>;
				status = "okay";
				reg = <0x12180000 0x2000>;
				interrupts = <0x0 0x66 0x4>;
				interrupt-names = "cmd_irq";
				clocks = <0xc 0x7a 0xc 0x70>;
				clock-names = "mclk", "apb_pclk";
				bus-width = <0x4>;
				cap-sd-highspeed;
				cap-mmc-highspeed;
				max-frequency = <0xb71b000>;
				no-1-8-v;
				dmas = <0x3c 0x2 0x3c 0x1>;
				dma-names = "tx", "rx";
				vmmc-supply = <0x3d>;
				pinctrl-names = "default";
				pinctrl-0 = <0x3e>;
				cd-gpios = <0x20 0x1a 0x1>;
			};

			sdcc@121c0000 {
				compatible = "arm,pl18x", "arm,primecell";
				arm,primecell-periphid = <0x51180>;
				status = "okay";
				reg = <0x121c0000 0x2000>;
				interrupts = <0x0 0x65 0x4>;
				interrupt-names = "cmd_irq";
				clocks = <0xc 0x7b 0xc 0x71>;
				clock-names = "mclk", "apb_pclk";
				bus-width = <0x4>;
				cap-sd-highspeed;
				cap-mmc-highspeed;
				max-frequency = <0x2dc6c00>;
				dmas = <0x3f 0x2 0x3f 0x1>;
				dma-names = "tx", "rx";
				pinctrl-names = "default";
				pinctrl-0 = <0x40>;
				vmmc-supply = <0x41>;
				vqmmc-supply = <0x42>;
				mmc-pwrseq = <0x43>;
			};
		};

		syscon@1a400000 {
			compatible = "qcom,tcsr-apq8064", "syscon";
			reg = <0x1a400000 0x100>;
			phandle = <0x15>;
		};

		adreno-3xx@4300000 {
			compatible = "qcom,adreno-3xx";
			reg = <0x4300000 0x20000>;
			reg-names = "kgsl_3d0_reg_memory";
			interrupts = <0x0 0x50 0x4>;
			interrupt-names = "kgsl_3d0_irq";
			clock-names = "core_clk", "iface_clk", "mem_clk", "mem_iface_clk";
			clocks = <0x44 0x47 0x44 0x16 0x44 0x21 0x44 0x13>;
			qcom,chipid = <0x3020002>;
			iommus = <0x45 0x0 0x45 0x1 0x45 0x2 0x45 0x3 0x45 0x4 0x45 0x5 0x45 0x6 0x45 0x7 0x45 0x8 0x45 0x9 0x45 0xa 0x45 0xb 0x45 0xc 0x45 0xd 0x45 0xe 0x45 0xf 0x45 0x10 0x45 0x11 0x45 0x12 0x45 0x13 0x45 0x14 0x45 0x15 0x45 0x16 0x45 0x17 0x45 0x18 0x45 0x19 0x45 0x1a 0x45 0x1b 0x45 0x1c 0x45 0x1d 0x45 0x1e 0x45 0x1f 0x46 0x0 0x46 0x1 0x46 0x2 0x46 0x3 0x46 0x4 0x46 0x5 0x46 0x6 0x46 0x7 0x46 0x8 0x46 0x9 0x46 0xa 0x46 0xb 0x46 0xc 0x46 0xd 0x46 0xe 0x46 0xf 0x46 0x10 0x46 0x11 0x46 0x12 0x46 0x13 0x46 0x14 0x46 0x15 0x46 0x16 0x46 0x17 0x46 0x18 0x46 0x19 0x46 0x1a 0x46 0x1b 0x46 0x1c 0x46 0x1d 0x46 0x1e 0x46 0x1f>;

			qcom,gpu-pwrlevels {
				compatible = "qcom,gpu-pwrlevels";

				qcom,gpu-pwrlevel@0 {
					qcom,gpu-freq = <0x1ad27480>;
				};

				qcom,gpu-pwrlevel@1 {
					qcom,gpu-freq = <0x19bfcc0>;
				};
			};
		};

		syscon@5700000 {
			compatible = "syscon";
			reg = <0x5700000 0x70>;
			phandle = <0x48>;
		};

		mdss_dsi@4700000 {
			compatible = "qcom,mdss-dsi-ctrl";
			label = "MDSS DSI CTRL->0";
			#address-cells = <0x1>;
			#size-cells = <0x0>;
			interrupts = <0x0 0x52 0x4>;
			reg = <0x4700000 0x200>;
			reg-names = "dsi_ctrl";
			clocks = <0x44 0x11 0x44 0x8 0x44 0x4 0x44 0x39 0x44 0x54 0x44 0x6a 0x44 0x58>;
			clock-names = "iface_clk", "bus_clk", "core_mmss_clk", "src_clk", "byte_clk", "pixel_clk", "core_clk";
			assigned-clocks = <0x44 0x53 0x44 0x57 0x44 0x38 0x44 0x69>;
			assigned-clock-parents = <0x47 0x0 0x47 0x0 0x47 0x1 0x47 0x1>;
			syscon-sfpb = <0x48>;
			phys = <0x47>;

			ports {
				#address-cells = <0x1>;
				#size-cells = <0x0>;

				port@0 {
					reg = <0x0>;

					endpoint {
					};
				};

				port@1 {
					reg = <0x1>;

					endpoint {
					};
				};
			};
		};

		dsi-phy@4700200 {
			compatible = "qcom,dsi-phy-28nm-8960";
			#clock-cells = <0x1>;
			#phy-cells = <0x0>;
			reg = <0x4700200 0x100 0x4700300 0x200 0x4700500 0x5c>;
			reg-names = "dsi_pll", "dsi_phy", "dsi_phy_regulator";
			clock-names = "iface_clk";
			clocks = <0x44 0x11>;
			phandle = <0x47>;
		};

		iommu@7500000 {
			compatible = "qcom,apq8064-iommu";
			#iommu-cells = <0x1>;
			clock-names = "smmu_pclk", "iommu_clk";
			clocks = <0x44 0xb 0x44 0x1e>;
			reg = <0x7500000 0x100000>;
			interrupts = <0x0 0x3f 0x4 0x0 0x40 0x4>;
			qcom,ncb = <0x2>;
			phandle = <0x51>;
		};

		iommu@7600000 {
			compatible = "qcom,apq8064-iommu";
			#iommu-cells = <0x1>;
			clock-names = "smmu_pclk", "iommu_clk";
			clocks = <0x44 0xb 0x44 0x1e>;
			reg = <0x7600000 0x100000>;
			interrupts = <0x0 0x3d 0x4 0x0 0x3e 0x4>;
			qcom,ncb = <0x2>;
			phandle = <0x52>;
		};

		iommu@7c00000 {
			compatible = "qcom,apq8064-iommu";
			#iommu-cells = <0x1>;
			clock-names = "smmu_pclk", "iommu_clk";
			clocks = <0x44 0xb 0x44 0x21>;
			reg = <0x7c00000 0x100000>;
			interrupts = <0x0 0x45 0x4 0x0 0x46 0x4>;
			qcom,ncb = <0x3>;
			phandle = <0x45>;
		};

		iommu@7d00000 {
			compatible = "qcom,apq8064-iommu";
			#iommu-cells = <0x1>;
			clock-names = "smmu_pclk", "iommu_clk";
			clocks = <0x44 0xb 0x44 0x21>;
			reg = <0x7d00000 0x100000>;
			interrupts = <0x0 0xd2 0x4 0x0 0xd3 0x4>;
			qcom,ncb = <0x3>;
			phandle = <0x46>;
		};

		pci@1b500000 {
			compatible = "qcom,pcie-apq8064", "snps,dw-pcie";
			reg = <0x1b500000 0x1000 0x1b502000 0x80 0x1b600000 0x100 0xff00000 0x100000>;
			reg-names = "dbi", "elbi", "parf", "config";
			device_type = "pci";
			linux,pci-domain = <0x0>;
			bus-range = <0x0 0xff>;
			num-lanes = <0x1>;
			#address-cells = <0x3>;
			#size-cells = <0x2>;
			ranges = <0x81000000 0x0 0x0 0xfe00000 0x0 0x100000 0x82000000 0x0 0x8000000 0x8000000 0x0 0x7e00000>;
			interrupts = <0x0 0xee 0x4>;
			interrupt-names = "msi";
			#interrupt-cells = <0x1>;
			interrupt-map-mask = <0x0 0x0 0x0 0x7>;
			interrupt-map = <0x0 0x0 0x0 0x1 0x1 0x0 0x24 0x4 0x0 0x0 0x0 0x2 0x1 0x0 0x25 0x4 0x0 0x0 0x0 0x3 0x1 0x0 0x26 0x4 0x0 0x0 0x0 0x4 0x1 0x0 0x27 0x4>;
			clocks = <0xc 0x2b 0xc 0x2e 0xc 0x2d>;
			clock-names = "core", "iface", "phy";
			resets = <0xc 0x6c 0xc 0x6b 0xc 0x6a 0xc 0x69 0xc 0x68>;
			reset-names = "axi", "ahb", "por", "pci", "phy";
			status = "ok";
			vdda-supply = <0x49>;
			vdda_phy-supply = <0x4a>;
			vdda_refclk-supply = <0x41>;
			pinctrl-0 = <0x4b>;
			pinctrl-names = "default";
			perst-gpio = <0x20 0x1b 0x1>;
		};

		hdmi-tx@4a00000 {
			compatible = "qcom,hdmi-tx-8960";
			pinctrl-names = "default";
			pinctrl-0 = <0x4c>;
			reg = <0x4a00000 0x2f0>;
			reg-names = "core_physical";
			interrupts = <0x0 0x4f 0x4>;
			clocks = <0x44 0x3e 0x44 0xc 0x44 0x15>;
			clock-names = "core_clk", "master_iface_clk", "slave_iface_clk";
			phys = <0x4d>;
			phy-names = "hdmi-phy";
			status = "okay";
			core-vdda-supply = <0x4e>;
			hdmi-mux-supply = <0x41>;
			hpd-gpios = <0x20 0x48 0x0>;

			ports {
				#address-cells = <0x1>;
				#size-cells = <0x0>;

				port@0 {
					reg = <0x0>;

					endpoint {
						remote-endpoint = <0x4f>;
						phandle = <0x53>;
					};
				};

				port@1 {
					reg = <0x1>;

					endpoint {
						remote-endpoint = <0x50>;
						phandle = <0x71>;
					};
				};
			};
		};

		hdmi-phy@4a00400 {
			compatible = "qcom,hdmi-phy-8960";
			reg = <0x4a00400 0x60 0x4a00500 0x100>;
			reg-names = "hdmi_phy", "hdmi_pll";
			clocks = <0x44 0x15>;
			clock-names = "slave_iface_clk";
			#phy-cells = <0x0>;
			status = "okay";
			core-vdda-supply = <0x4e>;
			phandle = <0x4d>;
		};

		mdp@5100000 {
			compatible = "qcom,mdp4";
			reg = <0x5100000 0xf0000>;
			interrupts = <0x0 0x4b 0x4>;
			clocks = <0x44 0x4d 0x44 0x10 0x44 0x1e 0x44 0x4e 0x44 0x5f 0x44 0x60>;
			clock-names = "core_clk", "iface_clk", "bus_clk", "lut_clk", "hdmi_clk", "tv_clk";
			iommus = <0x51 0x0 0x51 0x2 0x52 0x0 0x52 0x2>;
			status = "okay";

			ports {
				#address-cells = <0x1>;
				#size-cells = <0x0>;

				port@0 {
					reg = <0x0>;

					endpoint {
					};
				};

				port@1 {
					reg = <0x1>;

					endpoint {
					};
				};

				port@2 {
					reg = <0x2>;

					endpoint {
					};
				};

				port@3 {
					reg = <0x3>;

					endpoint {
						remote-endpoint = <0x53>;
						phandle = <0x4f>;
					};
				};
			};
		};

		riva-pil@3204000 {
			compatible = "qcom,riva-pil";
			reg = <0x3200800 0x1000 0x3202000 0x2000 0x3204000 0x100>;
			reg-names = "ccu", "dxe", "pmu";
			interrupts-extended = <0x1 0x0 0xc7 0x1 0x54 0x6 0x1>;
			interrupt-names = "wdog", "fatal";
			memory-region = <0x55>;
			vddcx-supply = <0x49>;
			vddmx-supply = <0x56>;
			vddpx-supply = <0x2a>;
			status = "disabled";
			phandle = <0x5a>;

			iris {
				compatible = "qcom,wcn3660";
				clocks = <0x2f>;
				clock-names = "xo";
				vddxo-supply = <0x32>;
				vddrfa-supply = <0x57>;
				vddpa-supply = <0x58>;
				vdddig-supply = <0x59>;
			};

			smd-edge {
				interrupts = <0x0 0xc6 0x1>;
				qcom,ipc = <0x10 0x8 0x19>;
				qcom,smd-edge = <0x6>;
				label = "riva";

				wcnss {
					compatible = "qcom,wcnss";
					qcom,smd-channels = "WCNSS_CTRL";
					qcom,mmio = <0x5a>;

					bt {
						compatible = "qcom,wcnss-bt";
					};

					wifi {
						compatible = "qcom,wcnss-wlan";
						interrupts = <0x0 0xcb 0x4 0x0 0xca 0x4>;
						interrupt-names = "tx", "rx";
						qcom,smem-states = <0x5b 0xa 0x5b 0x9>;
						qcom,smem-state-names = "tx-enable", "tx-rings-empty";
					};
				};
			};
		};

		etb@1a01000 {
			compatible = "coresight-etb10", "arm,primecell";
			reg = <0x1a01000 0x1000>;
			clocks = <0x12 0x8>;
			clock-names = "apb_pclk";

			in-ports {

				port {

					endpoint {
						remote-endpoint = <0x5c>;
						phandle = <0x5e>;
					};
				};
			};
		};

		tpiu@1a03000 {
			compatible = "arm,coresight-tpiu", "arm,primecell";
			reg = <0x1a03000 0x1000>;
			clocks = <0x12 0x8>;
			clock-names = "apb_pclk";

			in-ports {

				port {

					endpoint {
						remote-endpoint = <0x5d>;
						phandle = <0x5f>;
					};
				};
			};
		};

		replicator {
			compatible = "arm,coresight-replicator";
			clocks = <0x12 0x8>;
			clock-names = "apb_pclk";

			out-ports {
				#address-cells = <0x1>;
				#size-cells = <0x0>;

				port@0 {
					reg = <0x0>;

					endpoint {
						remote-endpoint = <0x5e>;
						phandle = <0x5c>;
					};
				};

				port@1 {
					reg = <0x1>;

					endpoint {
						remote-endpoint = <0x5f>;
						phandle = <0x5d>;
					};
				};
			};

			in-ports {

				port {

					endpoint {
						remote-endpoint = <0x60>;
						phandle = <0x65>;
					};
				};
			};
		};

		funnel@1a04000 {
			compatible = "arm,coresight-funnel", "arm,primecell";
			reg = <0x1a04000 0x1000>;
			clocks = <0x12 0x8>;
			clock-names = "apb_pclk";

			in-ports {
				#address-cells = <0x1>;
				#size-cells = <0x0>;

				port@0 {
					reg = <0x0>;

					endpoint {
						remote-endpoint = <0x61>;
						phandle = <0x67>;
					};
				};

				port@1 {
					reg = <0x1>;

					endpoint {
						remote-endpoint = <0x62>;
						phandle = <0x69>;
					};
				};

				port@4 {
					reg = <0x4>;

					endpoint {
						remote-endpoint = <0x63>;
						phandle = <0x6b>;
					};
				};

				port@5 {
					reg = <0x5>;

					endpoint {
						remote-endpoint = <0x64>;
						phandle = <0x6d>;
					};
				};
			};

			out-ports {

				port {

					endpoint {
						remote-endpoint = <0x65>;
						phandle = <0x60>;
					};
				};
			};
		};

		etm@1a1c000 {
			compatible = "arm,coresight-etm3x", "arm,primecell";
			reg = <0x1a1c000 0x1000>;
			clocks = <0x12 0x8>;
			clock-names = "apb_pclk";
			cpu = <0x66>;

			out-ports {

				port {

					endpoint {
						remote-endpoint = <0x67>;
						phandle = <0x61>;
					};
				};
			};
		};

		etm@1a1d000 {
			compatible = "arm,coresight-etm3x", "arm,primecell";
			reg = <0x1a1d000 0x1000>;
			clocks = <0x12 0x8>;
			clock-names = "apb_pclk";
			cpu = <0x68>;

			out-ports {

				port {

					endpoint {
						remote-endpoint = <0x69>;
						phandle = <0x62>;
					};
				};
			};
		};

		etm@1a1e000 {
			compatible = "arm,coresight-etm3x", "arm,primecell";
			reg = <0x1a1e000 0x1000>;
			clocks = <0x12 0x8>;
			clock-names = "apb_pclk";
			cpu = <0x6a>;

			out-ports {

				port {

					endpoint {
						remote-endpoint = <0x6b>;
						phandle = <0x63>;
					};
				};
			};
		};

		etm@1a1f000 {
			compatible = "arm,coresight-etm3x", "arm,primecell";
			reg = <0x1a1f000 0x1000>;
			clocks = <0x12 0x8>;
			clock-names = "apb_pclk";
			cpu = <0x6c>;

			out-ports {

				port {

					endpoint {
						remote-endpoint = <0x6d>;
						phandle = <0x64>;
					};
				};
			};
		};

		regulator-fixed@1 {
			compatible = "regulator-fixed";
			regulator-min-microvolt = <0x325aa0>;
			regulator-max-microvolt = <0x325aa0>;
			regulator-name = "ext_3p3v";
			regulator-type = "voltage";
			startup-delay-us = <0x0>;
			gpio = <0x20 0x4d 0x0>;
			enable-active-high;
			regulator-boot-on;
			phandle = <0x41>;
		};
	};

	pwrseq {
		compatible = "simple-bus";

		sdcc4_pwrseq {
			pinctrl-names = "default";
			pinctrl-0 = <0x6e>;
			compatible = "mmc-pwrseq-simple";
			reset-gpios = <0x6f 0x2b 0x1>;
			phandle = <0x43>;
		};
	};

	leds {
		compatible = "gpio-leds";
		pinctrl-names = "default";
		pinctrl-0 = <0x70>;

		led@1 {
			label = "apq8064:green:user1";
			gpios = <0x6f 0x12 0x0>;
			default-state = "on";
		};
	};

	hdmi-out {
		compatible = "hdmi-connector";
		type = [64 00];

		port {

			endpoint {
				remote-endpoint = <0x71>;
				phandle = <0x50>;
			};
		};
	};
};
